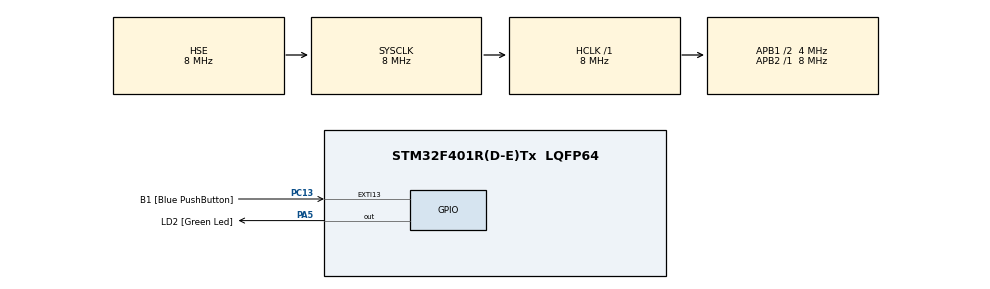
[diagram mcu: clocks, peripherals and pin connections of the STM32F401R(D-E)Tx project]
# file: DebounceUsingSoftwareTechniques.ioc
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Mcu.Family=STM32F4
Mcu.Name=STM32F401R(D-E)Tx
Mcu.Package=LQFP64
NVIC.PriorityGroup=NVIC_PRIORITYGROUP_0
PA5.GPIO_Label=LD2 [Green Led]
PA5.GPIO_Mode=GPIO_MODE_OUTPUT_PP
PA5.GPIO_PuPd=GPIO_NOPULL
PA5.GPIO_Speed=GPIO_SPEED_FREQ_LOW
PA5.Signal=GPIO_Output
PB3.GPIO_Label=SWO
PB3.Signal=SYS_JTDO-SWO
PC13-ANTI_TAMP.GPIO_Label=B1 [Blue PushButton]
PC13-ANTI_TAMP.GPIO_ModeDefaultEXTI=GPIO_MODE_IT_FALLING
PC13-ANTI_TAMP.GPIO_PuPd=GPIO_NOPULL
PC13-ANTI_TAMP.Signal=GPXTI13
PH0\ -\ OSC_IN.Mode=HSE-External-Clock-Source
PH0\ -\ OSC_IN.Signal=RCC_OSC_IN
PH1\ -\ OSC_OUT.Mode=HSE-External-Clock-Source
PH1\ -\ OSC_OUT.Signal=RCC_OSC_OUT
ProjectManager.HeapSize=0x200
ProjectManager.StackSize=0x400
ProjectManager.TargetToolchain=CMake
RCC.48MHZClocksFreq_Value=24000000
RCC.AHBFreq_Value=8000000
RCC.APB1CLKDivider=RCC_HCLK_DIV2
RCC.APB1Freq_Value=4000000
RCC.APB1TimFreq_Value=8000000
RCC.APB2Freq_Value=8000000
RCC.APB2TimFreq_Value=8000000
RCC.CortexFreq_Value=8000000
RCC.EnbaleCSS=true
RCC.HCLKFreq_Value=8000000
RCC.HSE_VALUE=8000000
RCC.HSI_VALUE=16000000
RCC.PLLN=336
RCC.PLLP=RCC_PLLP_DIV4
RCC.PLLQ=7
RCC.PLLSourceVirtual=RCC_PLLSOURCE_HSE
RCC.SYSCLKFreq_VALUE=8000000
RCC.SYSCLKSource=RCC_SYSCLKSOURCE_HSE
RCC.VCOOutputFreq_Value=168000000
board=NUCLEO-F401RE

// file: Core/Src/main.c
/* USER CODE BEGIN Header */
/**
  ******************************************************************************
  * @file           : main.c
  * @brief          : Main program body
  ******************************************************************************
  * @attention
  *
  * Copyright (c) 2025 STMicroelectronics.
  * All rights reserved.
  *
  * This software is licensed under terms that can be found in the LICENSE file
  * in the root directory of this software component.
  * If no LICENSE file comes with this software, it is provided AS-IS.
  *
  ******************************************************************************
  */
/* USER CODE END Header */
#include "main.h"

/* USER CODE BEGIN PD */
#define DEBOUNCE_TIME 70
#define DEBOUNCE_COUNTER  5
/* USER CODE END PD */

void SystemClock_Config(void);
static void MX_GPIO_Init(void);

/* USER CODE BEGIN 0 */
int DebounceReadPinUsingHALDelay(GPIO_TypeDef *GPIOx,uint16_t GPIO_Pin){
    uint16_t isButtonPushed = 0;

    if(HAL_GPIO_ReadPin(GPIOx,GPIO_Pin) == 0){
      HAL_Delay(DEBOUNCE_TIME);

      if(HAL_GPIO_ReadPin(GPIOx,GPIO_Pin) == RESET){
        isButtonPushed = 1;
        return isButtonPushed;
      }

    }

    return 0;

}

int DebouncingUsingGetTick(GPIO_TypeDef *GPIOx,uint16_t GPIO_Pin){
  static uint8_t isButtonPushedGetTick = 0;
  static uint32_t lastDebounce = 0;

  uint8_t currentState = HAL_GPIO_ReadPin(GPIOx,GPIO_Pin);

  if( currentState != isButtonPushedGetTick){
    if((HAL_GetTick()-lastDebounce)>DEBOUNCE_TIME){
      lastDebounce = HAL_GetTick();
      isButtonPushedGetTick = currentState;

      if(isButtonPushedGetTick == 0){

        return 1;
      }

    }
  }
  return 0;
}

int ReadPinUsingCountingMethod(GPIO_TypeDef *GPIOx,uint16_t GPIO_Pin){

  static uint8_t buttonStateCounting = 0;
  static uint8_t stableCounter = 0;

  if(HAL_GPIO_ReadPin(GPIOx,GPIO_Pin) == 0){
    if(stableCounter < DEBOUNCE_COUNTER ) stableCounter++;
  }
  else{
    if(stableCounter>0)stableCounter--;
  }

  if(stableCounter == DEBOUNCE_COUNTER){
    return 1;
  }
  else{return 0;}

}
/* USER CODE END 0 */

int main(void)
{

  /* MCU Configuration--------------------------------------------------------*/

  /* Reset of all peripherals, Initializes the Flash interface and the Systick. */
  HAL_Init();

  /* Configure the system clock */
  SystemClock_Config();

  /* Initialize all configured peripherals */
  MX_GPIO_Init();

  /* Infinite loop */
  /* USER CODE BEGIN WHILE */
  while (1)
  {

    /*Uncomment each if statement to see the difference*/

    // if(DebounceReadPinUsingHALDelay(GPIOC,GPIO_PIN_13)){
    //   HAL_GPIO_TogglePin(GPIOA,GPIO_PIN_5);
    // }

    if(DebouncingUsingGetTick(GPIOC,GPIO_PIN_13)){
      HAL_GPIO_TogglePin(GPIOA,GPIO_PIN_5);
    }

    // if(ReadPinUsingCountingMethod(GPIOC,GPIO_PIN_13)){

    //     HAL_GPIO_TogglePin(GPIOA, GPIO_PIN_5);

    // }

    /* USER CODE END WHILE */

  }
}

void SystemClock_Config(void)
{
  RCC_OscInitTypeDef RCC_OscInitStruct = {0};
  RCC_ClkInitTypeDef RCC_ClkInitStruct = {0};

  /** Configure the main internal regulator output voltage
  */
  __HAL_RCC_PWR_CLK_ENABLE();
  __HAL_PWR_VOLTAGESCALING_CONFIG(PWR_REGULATOR_VOLTAGE_SCALE2);

  /** Initializes the RCC Oscillators according to the specified parameters
  * in the RCC_OscInitTypeDef structure.
  */
  RCC_OscInitStruct.OscillatorType = RCC_OSCILLATORTYPE_HSE;
  RCC_OscInitStruct.HSEState = RCC_HSE_BYPASS;
  RCC_OscInitStruct.PLL.PLLState = RCC_PLL_NONE;
  if (HAL_RCC_OscConfig(&RCC_OscInitStruct) != HAL_OK)
  {
    Error_Handler();
  }

  /** Initializes the CPU, AHB and APB buses clocks
  */
  RCC_ClkInitStruct.ClockType = RCC_CLOCKTYPE_HCLK|RCC_CLOCKTYPE_SYSCLK
                              |RCC_CLOCKTYPE_PCLK1|RCC_CLOCKTYPE_PCLK2;
  RCC_ClkInitStruct.SYSCLKSource = RCC_SYSCLKSOURCE_HSE;
  RCC_ClkInitStruct.AHBCLKDivider = RCC_SYSCLK_DIV1;
  RCC_ClkInitStruct.APB1CLKDivider = RCC_HCLK_DIV2;
  RCC_ClkInitStruct.APB2CLKDivider = RCC_HCLK_DIV1;

  if (HAL_RCC_ClockConfig(&RCC_ClkInitStruct, FLASH_LATENCY_0) != HAL_OK)
  {
    Error_Handler();
  }

  /** Enables the Clock Security System
  */
  HAL_RCC_EnableCSS();
}

static void MX_GPIO_Init(void)
{
  GPIO_InitTypeDef GPIO_InitStruct = {0};

  /* GPIO Ports Clock Enable */
  __HAL_RCC_GPIOC_CLK_ENABLE();
  __HAL_RCC_GPIOH_CLK_ENABLE();
  __HAL_RCC_GPIOA_CLK_ENABLE();
  __HAL_RCC_GPIOB_CLK_ENABLE();

  /*Configure GPIO pin Output Level */
  HAL_GPIO_WritePin(LD2_GPIO_Port, LD2_Pin, GPIO_PIN_RESET);

  /*Configure GPIO pin : B1_Pin */
  GPIO_InitStruct.Pin = B1_Pin;
  GPIO_InitStruct.Mode = GPIO_MODE_IT_FALLING;
  GPIO_InitStruct.Pull = GPIO_NOPULL;
  HAL_GPIO_Init(B1_GPIO_Port, &GPIO_InitStruct);

  /*Configure GPIO pin : LD2_Pin */
  GPIO_InitStruct.Pin = LD2_Pin;
  GPIO_InitStruct.Mode = GPIO_MODE_OUTPUT_PP;
  GPIO_InitStruct.Pull = GPIO_NOPULL;
  GPIO_InitStruct.Speed = GPIO_SPEED_FREQ_LOW;
  HAL_GPIO_Init(LD2_GPIO_Port, &GPIO_InitStruct);

}

void Error_Handler(void)
{
  __disable_irq();
  while (1)
  {
  }
}
